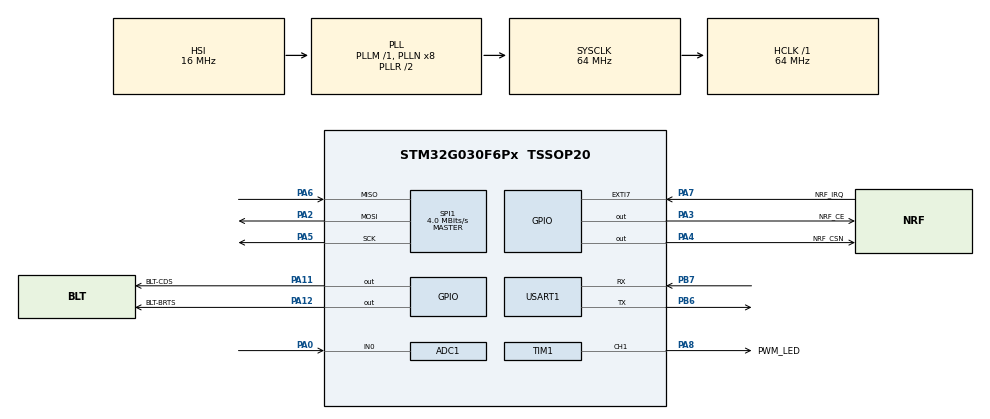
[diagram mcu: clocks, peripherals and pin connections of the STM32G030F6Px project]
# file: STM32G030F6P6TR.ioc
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ADC1.Channel-1\#ChannelRegularConversion=ADC_CHANNEL_0
ADC1.NbrOfConversion=1
ADC1.NbrOfConversionFlag=1
ADC1.Rank-1\#ChannelRegularConversion=1
ADC1.SamplingTime-1\#ChannelRegularConversion=ADC_SAMPLINGTIME_COMMON_1
ADC1.SelectedChannel=ADC_CHANNEL_0|ADC_CHANNEL_VREFINT
ADC1.master=1
Dma.Request0=SPI1_TX
Dma.Request1=USART1_RX
Dma.Request2=USART1_TX
Dma.SPI1_TX.0.Direction=DMA_MEMORY_TO_PERIPH
Dma.SPI1_TX.0.EventEnable=DISABLE
Dma.SPI1_TX.0.Instance=DMA1_Channel1
Dma.SPI1_TX.0.MemDataAlignment=DMA_MDATAALIGN_BYTE
Dma.SPI1_TX.0.MemInc=DMA_MINC_ENABLE
Dma.SPI1_TX.0.Mode=DMA_NORMAL
Dma.SPI1_TX.0.PeriphDataAlignment=DMA_PDATAALIGN_BYTE
Dma.SPI1_TX.0.PeriphInc=DMA_PINC_DISABLE
Dma.SPI1_TX.0.Polarity=HAL_DMAMUX_REQ_GEN_RISING
Dma.SPI1_TX.0.Priority=DMA_PRIORITY_LOW
Dma.SPI1_TX.0.RequestNumber=1
Dma.SPI1_TX.0.SignalID=NONE
Dma.SPI1_TX.0.SyncEnable=DISABLE
Dma.SPI1_TX.0.SyncPolarity=HAL_DMAMUX_SYNC_NO_EVENT
Dma.SPI1_TX.0.SyncRequestNumber=1
Dma.SPI1_TX.0.SyncSignalID=NONE
Dma.USART1_RX.1.Direction=DMA_PERIPH_TO_MEMORY
Dma.USART1_RX.1.EventEnable=DISABLE
Dma.USART1_RX.1.Instance=DMA1_Channel2
Dma.USART1_RX.1.MemDataAlignment=DMA_MDATAALIGN_BYTE
Dma.USART1_RX.1.MemInc=DMA_MINC_ENABLE
Dma.USART1_RX.1.Mode=DMA_CIRCULAR
Dma.USART1_RX.1.PeriphDataAlignment=DMA_PDATAALIGN_BYTE
Dma.USART1_RX.1.PeriphInc=DMA_PINC_DISABLE
Dma.USART1_RX.1.Polarity=HAL_DMAMUX_REQ_GEN_RISING
Dma.USART1_RX.1.Priority=DMA_PRIORITY_LOW
Dma.USART1_RX.1.RequestNumber=1
Dma.USART1_RX.1.SignalID=NONE
Dma.USART1_RX.1.SyncEnable=DISABLE
Dma.USART1_RX.1.SyncPolarity=HAL_DMAMUX_SYNC_NO_EVENT
Dma.USART1_RX.1.SyncRequestNumber=1
Dma.USART1_RX.1.SyncSignalID=NONE
Dma.USART1_TX.2.Direction=DMA_MEMORY_TO_PERIPH
Dma.USART1_TX.2.EventEnable=DISABLE
Dma.USART1_TX.2.Instance=DMA1_Channel3
Dma.USART1_TX.2.MemDataAlignment=DMA_MDATAALIGN_BYTE
Dma.USART1_TX.2.MemInc=DMA_MINC_ENABLE
Dma.USART1_TX.2.Mode=DMA_NORMAL
Dma.USART1_TX.2.PeriphDataAlignment=DMA_PDATAALIGN_BYTE
Dma.USART1_TX.2.PeriphInc=DMA_PINC_DISABLE
Dma.USART1_TX.2.Polarity=HAL_DMAMUX_REQ_GEN_RISING
Dma.USART1_TX.2.Priority=DMA_PRIORITY_LOW
Dma.USART1_TX.2.RequestNumber=1
Dma.USART1_TX.2.SignalID=NONE
Dma.USART1_TX.2.SyncEnable=DISABLE
Dma.USART1_TX.2.SyncPolarity=HAL_DMAMUX_SYNC_NO_EVENT
Dma.USART1_TX.2.SyncRequestNumber=1
Dma.USART1_TX.2.SyncSignalID=NONE
FREERTOS.Tasks01=defaultTask,0,128,StartDefaultTask,Default,NULL,Dynamic,NULL,NULL
FREERTOS.configTOTAL_HEAP_SIZE=5630
Mcu.Family=STM32G0
Mcu.Name=STM32G030F6Px
Mcu.Package=TSSOP20
NVIC.DMA1_Channel1_IRQn=true\:3\:0\:false\:false\:true\:true\:false\:true\:true
NVIC.DMA1_Channel2_3_IRQn=true\:3\:0\:false\:false\:true\:true\:false\:true\:true
NVIC.USART1_IRQn=true\:3\:0\:false\:false\:true\:true\:true\:true\:true
PA0.Mode=IN0
PA0.Signal=ADC1_IN0
PA11\ [PA9].GPIO_Label=BLT-CDS
PA11\ [PA9].Signal=GPIO_Output
PA12\ [PA10].GPIO_Label=BLT-BRTS
PA12\ [PA10].Signal=GPIO_Output
PA13.Mode=Serial_Wire
PA13.Signal=SYS_SWDIO
PA14-BOOT0.Mode=Serial_Wire
PA14-BOOT0.Signal=SYS_SWCLK
PA14-BOOT0__PA15.StandardMode=true
PA2.Mode=Full_Duplex_Master
PA2.Signal=SPI1_MOSI
PA3.GPIO_Label=NRF_CE
PA3.Signal=GPIO_Output
PA4.GPIO_Label=NRF_CSN
PA4.Signal=GPIO_Output
PA5.Mode=Full_Duplex_Master
PA5.Signal=SPI1_SCK
PA6.Mode=Full_Duplex_Master
PA6.Signal=SPI1_MISO
PA7.GPIO_Label=NRF_IRQ
PA7.Signal=GPXTI7
PA8.GPIO_Label=PWM_LED
PA8.Signal=S_TIM1_CH1
PB0__PB1__PB2__PA8.StandardMode=true
PB3__PB4__PB5__PB6.StandardMode=true
PB6.Mode=Asynchronous
PB6.Signal=USART1_TX
PB7.Mode=Asynchronous
PB7.Signal=USART1_RX
PB7__PB8.StandardMode=true
PC14-OSC32_IN\ (PC14)__PB9.StandardMode=true
ProjectManager.HeapSize=0x200
ProjectManager.StackSize=0x400
ProjectManager.TargetToolchain=MDK-ARM V5.32
RCC.ADCFreq_Value=64000000
RCC.AHBFreq_Value=64000000
RCC.CortexFreq_Value=64000000
RCC.EXTERNAL_CLOCK_VALUE=12288000
RCC.HCLKFreq_Value=64000000
RCC.HSE_VALUE=8000000
RCC.HSI_VALUE=16000000
RCC.LSE_VALUE=32768
RCC.SYSCLKFreq_VALUE=64000000
RCC.SYSCLKSource=RCC_SYSCLKSOURCE_PLLCLK
RCC.VCOOutputFreq_Value=128000000
SH.S_TIM1_CH1.0=TIM1_CH1,Output Compare1 CH1
SPI1.BaudRatePrescaler=SPI_BAUDRATEPRESCALER_16
SPI1.CalculateBaudRate=4.0 MBits/s
SPI1.DataSize=SPI_DATASIZE_8BIT
SPI1.Direction=SPI_DIRECTION_2LINES
SPI1.Mode=SPI_MODE_MASTER
SPI1.VirtualType=VM_MASTER
TIM1.Channel-Output\ Compare1\ CH1=TIM_CHANNEL_1
USART1.VirtualMode-Asynchronous=VM_ASYNC
VP_ADC1_Vref_Input.Mode=IN-Vrefint
VP_FREERTOS_VS_CMSIS_V1.Mode=CMSIS_V1
VP_TIM1_VS_ClockSourceINT.Mode=Internal
board=custom

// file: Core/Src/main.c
/* USER CODE BEGIN Header */
/**
  ******************************************************************************
  * @file           : main.c
  * @brief          : Main program body
  ******************************************************************************
  * @attention
  *
  * Copyright (c) 2023 STMicroelectronics.
  * All rights reserved.
  *
  * This software is licensed under terms that can be found in the LICENSE file
  * in the root directory of this software component.
  * If no LICENSE file comes with this software, it is provided AS-IS.
  *
  ******************************************************************************
  */
/* USER CODE END Header */
#include "main.h"
#include "cmsis_os.h"
#include "adc.h"
#include "dma.h"
#include "spi.h"
#include "tim.h"
#include "usart.h"
#include "gpio.h"

/* USER CODE BEGIN Includes */
#include "../common.h"
/* USER CODE END Includes */

void SystemClock_Config(void);
void MX_FREERTOS_Init(void);

int main(void)
{

  /* MCU Configuration--------------------------------------------------------*/

  /* Reset of all peripherals, Initializes the Flash interface and the Systick. */
  HAL_Init();

  /* Configure the system clock */
  SystemClock_Config();

  /* Initialize all configured peripherals */
  MX_GPIO_Init();
  MX_DMA_Init();
  MX_ADC1_Init();
  MX_SPI1_Init();
  MX_TIM1_Init();
  MX_USART1_UART_Init();

  /* Call init function for freertos objects (in freertos.c) */
  MX_FREERTOS_Init();

  /* Start scheduler */
  osKernelStart();

  /* We should never get here as control is now taken by the scheduler */
  /* Infinite loop */
  while (1)
  {

  }
}

void SystemClock_Config(void)
{
  RCC_OscInitTypeDef RCC_OscInitStruct = {0};
  RCC_ClkInitTypeDef RCC_ClkInitStruct = {0};

  /** Configure the main internal regulator output voltage
  */
  HAL_PWREx_ControlVoltageScaling(PWR_REGULATOR_VOLTAGE_SCALE1);

  /** Initializes the RCC Oscillators according to the specified parameters
  * in the RCC_OscInitTypeDef structure.
  */
  RCC_OscInitStruct.OscillatorType = RCC_OSCILLATORTYPE_HSI;
  RCC_OscInitStruct.HSIState = RCC_HSI_ON;
  RCC_OscInitStruct.HSIDiv = RCC_HSI_DIV1;
  RCC_OscInitStruct.HSICalibrationValue = RCC_HSICALIBRATION_DEFAULT;
  RCC_OscInitStruct.PLL.PLLState = RCC_PLL_ON;
  RCC_OscInitStruct.PLL.PLLSource = RCC_PLLSOURCE_HSI;
  RCC_OscInitStruct.PLL.PLLM = RCC_PLLM_DIV1;
  RCC_OscInitStruct.PLL.PLLN = 8;
  RCC_OscInitStruct.PLL.PLLP = RCC_PLLP_DIV2;
  RCC_OscInitStruct.PLL.PLLR = RCC_PLLR_DIV2;
  if (HAL_RCC_OscConfig(&RCC_OscInitStruct) != HAL_OK)
  {
    Error_Handler();
  }

  /** Initializes the CPU, AHB and APB buses clocks
  */
  RCC_ClkInitStruct.ClockType = RCC_CLOCKTYPE_HCLK|RCC_CLOCKTYPE_SYSCLK
                              |RCC_CLOCKTYPE_PCLK1;
  RCC_ClkInitStruct.SYSCLKSource = RCC_SYSCLKSOURCE_PLLCLK;
  RCC_ClkInitStruct.AHBCLKDivider = RCC_SYSCLK_DIV1;
  RCC_ClkInitStruct.APB1CLKDivider = RCC_HCLK_DIV1;

  if (HAL_RCC_ClockConfig(&RCC_ClkInitStruct, FLASH_LATENCY_2) != HAL_OK)
  {
    Error_Handler();
  }
}

void Error_Handler(void)
{
  __disable_irq();
  while (1)
  {
  }
}

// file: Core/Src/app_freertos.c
/* USER CODE BEGIN Header */
/**
  ******************************************************************************
  * File Name          : app_freertos.c
  * Description        : Code for freertos applications
  ******************************************************************************
  * @attention
  *
  * Copyright (c) 2023 STMicroelectronics.
  * All rights reserved.
  *
  * This software is licensed under terms that can be found in the LICENSE file
  * in the root directory of this software component.
  * If no LICENSE file comes with this software, it is provided AS-IS.
  *
  ******************************************************************************
  */
/* USER CODE END Header */

#include "FreeRTOS.h"
#include "task.h"
#include "main.h"
#include "cmsis_os.h"

/* USER CODE BEGIN Includes */
#include "../common.h"
/* USER CODE END Includes */

/* USER CODE BEGIN Variables */
osThreadId debugTaskHandle;
/* USER CODE END Variables */
osThreadId defaultTaskHandle;

/* USER CODE BEGIN FunctionPrototypes */
void debugTaskFun(void const * argument);
/* USER CODE END FunctionPrototypes */

void StartDefaultTask(void const * argument);

void MX_FREERTOS_Init(void); /* (MISRA C 2004 rule 8.1) */

void MX_FREERTOS_Init(void) {

  /* Create the thread(s) */
  /* definition and creation of defaultTask */
  osThreadDef(defaultTask, StartDefaultTask, osPriorityNormal, 0, 128);
  defaultTaskHandle = osThreadCreate(osThread(defaultTask), NULL);

  /* USER CODE BEGIN RTOS_THREADS */
  /* add threads, ... */
	osThreadDef(debugTask, debugTaskFun, osPriorityNormal, 0, debugTaskSize);
  debugTaskHandle = osThreadCreate(osThread(debugTask), NULL);
  /* USER CODE END RTOS_THREADS */

}

void StartDefaultTask(void const * argument)
{
  /* USER CODE BEGIN StartDefaultTask */
  /* Infinite loop */
  for(;;)
  {
    //AT命令使能引脚 1:进入AT
		HAL_GPIO_WritePin( BLT_CDS_GPIO_Port, BLT_CDS_Pin, GPIO_PIN_SET );
		//AT命令使能引脚 0:退出AT
		//HAL_GPIO_WritePin( BLT_CDS_GPIO_Port, BLT_CDS_Pin, GPIO_PIN_RESET );

		//睡眠引脚 0:退出睡眠
		HAL_GPIO_WritePin( BLT_BRTS_GPIO_Port, BLT_BRTS_Pin, GPIO_PIN_RESET );

		vTaskDelete( defaultTaskHandle );
  }
  /* USER CODE END StartDefaultTask */
}

/* USER CODE BEGIN Application */
void debugTaskFun(void const * argument)
{
  for(;;)
  {
    //printf("STM32G030F6 Test\r\n");
		vTaskDelay(2000);
  }
}
/* USER CODE END Application */
